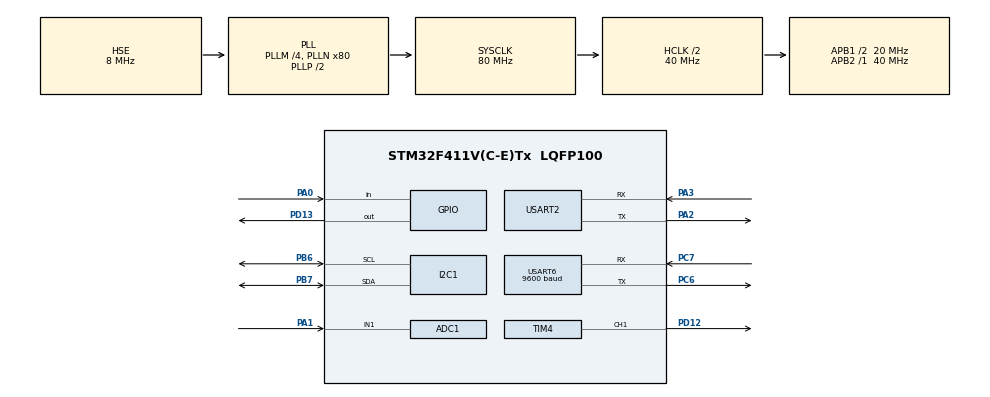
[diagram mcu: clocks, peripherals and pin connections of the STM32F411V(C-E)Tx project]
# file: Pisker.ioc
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ADC1.Channel-0\#ChannelRegularConversion=ADC_CHANNEL_1
ADC1.ClockPrescaler=ADC_CLOCK_SYNC_PCLK_DIV4
ADC1.ContinuousConvMode=ENABLE
ADC1.DMAContinuousRequests=ENABLE
ADC1.ExternalTrigConv=ADC_EXTERNALTRIGCONV_T3_TRGO
ADC1.NbrOfConversionFlag=1
ADC1.Rank-0\#ChannelRegularConversion=1
ADC1.SamplingTime-0\#ChannelRegularConversion=ADC_SAMPLETIME_3CYCLES
ADC1.master=1
Dma.ADC1.3.Direction=DMA_PERIPH_TO_MEMORY
Dma.ADC1.3.FIFOMode=DMA_FIFOMODE_DISABLE
Dma.ADC1.3.Instance=DMA2_Stream0
Dma.ADC1.3.MemDataAlignment=DMA_MDATAALIGN_HALFWORD
Dma.ADC1.3.MemInc=DMA_MINC_ENABLE
Dma.ADC1.3.Mode=DMA_CIRCULAR
Dma.ADC1.3.PeriphDataAlignment=DMA_PDATAALIGN_HALFWORD
Dma.ADC1.3.PeriphInc=DMA_PINC_DISABLE
Dma.ADC1.3.Priority=DMA_PRIORITY_LOW
Dma.Request0=TIM4_CH1
Dma.Request1=USART2_RX
Dma.Request2=USART6_RX
Dma.Request3=ADC1
Dma.TIM4_CH1.0.Direction=DMA_MEMORY_TO_PERIPH
Dma.TIM4_CH1.0.FIFOMode=DMA_FIFOMODE_DISABLE
Dma.TIM4_CH1.0.Instance=DMA1_Stream0
Dma.TIM4_CH1.0.MemDataAlignment=DMA_MDATAALIGN_HALFWORD
Dma.TIM4_CH1.0.MemInc=DMA_MINC_ENABLE
Dma.TIM4_CH1.0.Mode=DMA_NORMAL
Dma.TIM4_CH1.0.PeriphDataAlignment=DMA_PDATAALIGN_HALFWORD
Dma.TIM4_CH1.0.PeriphInc=DMA_PINC_DISABLE
Dma.TIM4_CH1.0.Priority=DMA_PRIORITY_LOW
Dma.USART2_RX.1.Direction=DMA_PERIPH_TO_MEMORY
Dma.USART2_RX.1.FIFOMode=DMA_FIFOMODE_DISABLE
Dma.USART2_RX.1.Instance=DMA1_Stream5
Dma.USART2_RX.1.MemDataAlignment=DMA_MDATAALIGN_BYTE
Dma.USART2_RX.1.MemInc=DMA_MINC_ENABLE
Dma.USART2_RX.1.Mode=DMA_CIRCULAR
Dma.USART2_RX.1.PeriphDataAlignment=DMA_PDATAALIGN_BYTE
Dma.USART2_RX.1.PeriphInc=DMA_PINC_DISABLE
Dma.USART2_RX.1.Priority=DMA_PRIORITY_LOW
Dma.USART6_RX.2.Direction=DMA_PERIPH_TO_MEMORY
Dma.USART6_RX.2.FIFOMode=DMA_FIFOMODE_DISABLE
Dma.USART6_RX.2.Instance=DMA2_Stream1
Dma.USART6_RX.2.MemDataAlignment=DMA_MDATAALIGN_BYTE
Dma.USART6_RX.2.MemInc=DMA_MINC_ENABLE
Dma.USART6_RX.2.Mode=DMA_CIRCULAR
Dma.USART6_RX.2.PeriphDataAlignment=DMA_PDATAALIGN_BYTE
Dma.USART6_RX.2.PeriphInc=DMA_PINC_DISABLE
Dma.USART6_RX.2.Priority=DMA_PRIORITY_LOW
Mcu.Family=STM32F4
Mcu.Name=STM32F411V(C-E)Tx
Mcu.Package=LQFP100
NVIC.DMA1_Stream0_IRQn=true\:0\:0\:false\:false\:true\:false\:true\:true
NVIC.DMA1_Stream5_IRQn=true\:0\:0\:false\:false\:true\:false\:true\:true
NVIC.DMA2_Stream0_IRQn=true\:0\:0\:false\:false\:true\:false\:true\:true
NVIC.DMA2_Stream1_IRQn=true\:0\:0\:false\:false\:true\:false\:true\:true
NVIC.I2C1_ER_IRQn=true\:0\:0\:false\:false\:true\:true\:true\:true
NVIC.I2C1_EV_IRQn=true\:0\:0\:false\:false\:true\:true\:true\:true
NVIC.PriorityGroup=NVIC_PRIORITYGROUP_4
NVIC.TIM3_IRQn=true\:0\:0\:false\:false\:true\:true\:true\:true
NVIC.TIM4_IRQn=true\:0\:0\:false\:false\:true\:true\:true\:true
NVIC.USART2_IRQn=true\:0\:0\:false\:false\:true\:true\:true\:true
NVIC.USART6_IRQn=true\:0\:0\:false\:false\:true\:true\:true\:true
PA0-WKUP.Signal=GPIO_Input
PA1.Signal=ADCx_IN1
PA13.Mode=Serial_Wire
PA13.Signal=SYS_JTMS-SWDIO
PA14.Mode=Serial_Wire
PA14.Signal=SYS_JTCK-SWCLK
PA2.Mode=Asynchronous
PA2.Signal=USART2_TX
PA3.Mode=Asynchronous
PA3.Signal=USART2_RX
PB6.Mode=I2C
PB6.Signal=I2C1_SCL
PB7.Mode=I2C
PB7.Signal=I2C1_SDA
PC6.Mode=Asynchronous
PC6.Signal=USART6_TX
PC7.Mode=Asynchronous
PC7.Signal=USART6_RX
PD12.Signal=S_TIM4_CH1
PD13.Signal=GPIO_Output
PH0\ -\ OSC_IN.Mode=HSE-External-Oscillator
PH0\ -\ OSC_IN.Signal=RCC_OSC_IN
PH1\ -\ OSC_OUT.Mode=HSE-External-Oscillator
PH1\ -\ OSC_OUT.Signal=RCC_OSC_OUT
ProjectManager.HeapSize=0x200
ProjectManager.StackSize=0x400
ProjectManager.TargetToolchain=STM32CubeIDE
RCC.48MHZClocksFreq_Value=40000000
RCC.AHBCLKDivider=RCC_SYSCLK_DIV2
RCC.AHBFreq_Value=40000000
RCC.APB1CLKDivider=RCC_HCLK_DIV2
RCC.APB1Freq_Value=20000000
RCC.APB1TimFreq_Value=40000000
RCC.APB2Freq_Value=40000000
RCC.APB2TimFreq_Value=40000000
RCC.CortexFreq_Value=40000000
RCC.HCLKFreq_Value=40000000
RCC.HSE_VALUE=8000000
RCC.HSI_VALUE=16000000
RCC.LSE_VALUE=32768
RCC.PLLI2SM=4
RCC.PLLI2SN=50
RCC.PLLM=4
RCC.PLLN=80
RCC.PLLSourceVirtual=RCC_PLLSOURCE_HSE
RCC.SYSCLKFreq_VALUE=80000000
RCC.SYSCLKSource=RCC_SYSCLKSOURCE_PLLCLK
RCC.VCOOutputFreq_Value=160000000
SH.ADCx_IN1.0=ADC1_IN1,IN1
SH.S_TIM4_CH1.0=TIM4_CH1,PWM Generation1 CH1
STMicroelectronics.X-CUBE-ALGOBUILD.1.4.0.LibraryCcDSPOoLibraryJjDSPOoLibrary=true
TIM3.Period=25-1
TIM3.Prescaler=100-1
TIM3.TIM_MasterOutputTrigger=TIM_TRGO_UPDATE
TIM4.Channel-PWM\ Generation1\ CH1=TIM_CHANNEL_1
TIM4.Period=50-1
USART2.VirtualMode=VM_ASYNC
USART6.BaudRate=9600
USART6.VirtualMode=VM_ASYNC
VP_STMicroelectronics.X-CUBE-ALGOBUILD_VS_DSPOoLibraryJjLibrary_1.4.0_1.4.0.Mode=DSPOoLibraryJjLibrary
VP_TIM3_VS_ClockSourceINT.Mode=Internal
board=custom

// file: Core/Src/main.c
/* USER CODE BEGIN Header */
/**
 ******************************************************************************
 * @file           : main.c
 * @brief          : Main program body
 ******************************************************************************
 * @attention
 *
 * Copyright (c) 2024 STMicroelectronics.
 * All rights reserved.
 *
 * This software is licensed under terms that can be found in the LICENSE file
 * in the root directory of this software component.
 * If no LICENSE file comes with this software, it is provided AS-IS.
 *
 ******************************************************************************
 */
/* USER CODE END Header */
#include "main.h"

ADC_HandleTypeDef hadc1;
DMA_HandleTypeDef hdma_adc1;

I2C_HandleTypeDef hi2c1;

TIM_HandleTypeDef htim3;
TIM_HandleTypeDef htim4;
DMA_HandleTypeDef hdma_tim4_ch1;

UART_HandleTypeDef huart2;
UART_HandleTypeDef huart6;
DMA_HandleTypeDef hdma_usart2_rx;
DMA_HandleTypeDef hdma_usart6_rx;

/* USER CODE BEGIN PV */
btn_info_t button_state;
uint8_t uart_tx_buffer[TX_BUFFER_SIZE];
uint8_t uart_rx_buffer[RX_BUFFER_SIZE];
uint8_t uart_main_buffer[MAIN_BUFFER_SIZE];
/* USER CODE END PV */

void SystemClock_Config(void);
static void MX_GPIO_Init(void);
static void MX_DMA_Init(void);
static void MX_I2C1_Init(void);
static void MX_TIM4_Init(void);
static void MX_USART2_UART_Init(void);
static void MX_ADC1_Init(void);
static void MX_USART6_UART_Init(void);
static void MX_TIM3_Init(void);

int main(void)
{

  /* MCU Configuration--------------------------------------------------------*/

  /* Reset of all peripherals, Initializes the Flash interface and the Systick. */
  HAL_Init();

  /* Configure the system clock */
  SystemClock_Config();

  /* Initialize all configured peripherals */
  MX_GPIO_Init();
  MX_DMA_Init();
  MX_I2C1_Init();
  MX_TIM4_Init();
  MX_USART2_UART_Init();
  MX_ADC1_Init();
  MX_USART6_UART_Init();
  MX_TIM3_Init();
  /* USER CODE BEGIN 2 */
  //Init bsp
  bsp_adc_init(&hadc1, &hdma_adc1);
  bsp_i2c_init(&hi2c1);
  bsp_tim_init(&htim4);
  bsp_uart_pc_control_init(&huart2, &hdma_usart2_rx);
  bsp_uart_pc_control_buffer_init(uart_tx_buffer, uart_rx_buffer, RX_BUFFER_SIZE);
  bsp_uart_start_pc_control_receive();
  bsp_uart_dfp_init(&huart6, &hdma_usart6_rx);
  //system init
  sys_manager_init();
  //start Timer
  HAL_TIM_Base_Start_IT(&htim3);
  /* USER CODE END 2 */

  /* Infinite loop */
  while (1)
  {

    /* USER CODE BEGIN 3 */
    sys_manager_run(&button_state);
  }
  /* USER CODE END 3 */
}

void SystemClock_Config(void)
{
  RCC_OscInitTypeDef RCC_OscInitStruct = {0};
  RCC_ClkInitTypeDef RCC_ClkInitStruct = {0};

  /** Configure the main internal regulator output voltage
   */
  __HAL_RCC_PWR_CLK_ENABLE();
  __HAL_PWR_VOLTAGESCALING_CONFIG(PWR_REGULATOR_VOLTAGE_SCALE1);

  /** Initializes the RCC Oscillators according to the specified parameters
   * in the RCC_OscInitTypeDef structure.
   */
  RCC_OscInitStruct.OscillatorType = RCC_OSCILLATORTYPE_HSE;
  RCC_OscInitStruct.HSEState = RCC_HSE_ON;
  RCC_OscInitStruct.PLL.PLLState = RCC_PLL_ON;
  RCC_OscInitStruct.PLL.PLLSource = RCC_PLLSOURCE_HSE;
  RCC_OscInitStruct.PLL.PLLM = 4;
  RCC_OscInitStruct.PLL.PLLN = 80;
  RCC_OscInitStruct.PLL.PLLP = RCC_PLLP_DIV2;
  RCC_OscInitStruct.PLL.PLLQ = 4;
  if (HAL_RCC_OscConfig(&RCC_OscInitStruct) != HAL_OK)
  {
    Error_Handler();
  }

  /** Initializes the CPU, AHB and APB buses clocks
   */
  RCC_ClkInitStruct.ClockType = RCC_CLOCKTYPE_HCLK | RCC_CLOCKTYPE_SYSCLK | RCC_CLOCKTYPE_PCLK1 | RCC_CLOCKTYPE_PCLK2;
  RCC_ClkInitStruct.SYSCLKSource = RCC_SYSCLKSOURCE_PLLCLK;
  RCC_ClkInitStruct.AHBCLKDivider = RCC_SYSCLK_DIV2;
  RCC_ClkInitStruct.APB1CLKDivider = RCC_HCLK_DIV2;
  RCC_ClkInitStruct.APB2CLKDivider = RCC_HCLK_DIV1;

  if (HAL_RCC_ClockConfig(&RCC_ClkInitStruct, FLASH_LATENCY_1) != HAL_OK)
  {
    Error_Handler();
  }
}

static void MX_ADC1_Init(void)
{

  ADC_ChannelConfTypeDef sConfig = {0};

  /** Configure the global features of the ADC (Clock, Resolution, Data Alignment and number of conversion)
   */
  hadc1.Instance = ADC1;
  hadc1.Init.ClockPrescaler = ADC_CLOCK_SYNC_PCLK_DIV4;
  hadc1.Init.Resolution = ADC_RESOLUTION_12B;
  hadc1.Init.ScanConvMode = DISABLE;
  hadc1.Init.ContinuousConvMode = ENABLE;
  hadc1.Init.DiscontinuousConvMode = DISABLE;
  hadc1.Init.ExternalTrigConvEdge = ADC_EXTERNALTRIGCONVEDGE_RISING;
  hadc1.Init.ExternalTrigConv = ADC_EXTERNALTRIGCONV_T3_TRGO;
  hadc1.Init.DataAlign = ADC_DATAALIGN_RIGHT;
  hadc1.Init.NbrOfConversion = 1;
  hadc1.Init.DMAContinuousRequests = ENABLE;
  hadc1.Init.EOCSelection = ADC_EOC_SINGLE_CONV;
  if (HAL_ADC_Init(&hadc1) != HAL_OK)
  {
    Error_Handler();
  }

  /** Configure for the selected ADC regular channel its corresponding rank in the sequencer and its sample time.
   */
  sConfig.Channel = ADC_CHANNEL_1;
  sConfig.Rank = 1;
  sConfig.SamplingTime = ADC_SAMPLETIME_3CYCLES;
  if (HAL_ADC_ConfigChannel(&hadc1, &sConfig) != HAL_OK)
  {
    Error_Handler();
  }
}

static void MX_I2C1_Init(void)
{

  hi2c1.Instance = I2C1;
  hi2c1.Init.ClockSpeed = 100000;
  hi2c1.Init.DutyCycle = I2C_DUTYCYCLE_2;
  hi2c1.Init.OwnAddress1 = 0;
  hi2c1.Init.AddressingMode = I2C_ADDRESSINGMODE_7BIT;
  hi2c1.Init.DualAddressMode = I2C_DUALADDRESS_DISABLE;
  hi2c1.Init.OwnAddress2 = 0;
  hi2c1.Init.GeneralCallMode = I2C_GENERALCALL_DISABLE;
  hi2c1.Init.NoStretchMode = I2C_NOSTRETCH_DISABLE;
  if (HAL_I2C_Init(&hi2c1) != HAL_OK)
  {
    Error_Handler();
  }
}

static void MX_TIM3_Init(void)
{

  TIM_ClockConfigTypeDef sClockSourceConfig = {0};
  TIM_MasterConfigTypeDef sMasterConfig = {0};

  htim3.Instance = TIM3;
  htim3.Init.Prescaler = 100 - 1;
  htim3.Init.CounterMode = TIM_COUNTERMODE_UP;
  htim3.Init.Period = 25 - 1;
  htim3.Init.ClockDivision = TIM_CLOCKDIVISION_DIV1;
  htim3.Init.AutoReloadPreload = TIM_AUTORELOAD_PRELOAD_DISABLE;
  if (HAL_TIM_Base_Init(&htim3) != HAL_OK)
  {
    Error_Handler();
  }
  sClockSourceConfig.ClockSource = TIM_CLOCKSOURCE_INTERNAL;
  if (HAL_TIM_ConfigClockSource(&htim3, &sClockSourceConfig) != HAL_OK)
  {
    Error_Handler();
  }
  sMasterConfig.MasterOutputTrigger = TIM_TRGO_UPDATE;
  sMasterConfig.MasterSlaveMode = TIM_MASTERSLAVEMODE_DISABLE;
  if (HAL_TIMEx_MasterConfigSynchronization(&htim3, &sMasterConfig) != HAL_OK)
  {
    Error_Handler();
  }
}

static void MX_TIM4_Init(void)
{

  TIM_MasterConfigTypeDef sMasterConfig = {0};
  TIM_OC_InitTypeDef sConfigOC = {0};

  htim4.Instance = TIM4;
  htim4.Init.Prescaler = 0;
  htim4.Init.CounterMode = TIM_COUNTERMODE_UP;
  htim4.Init.Period = 50 - 1;
  htim4.Init.ClockDivision = TIM_CLOCKDIVISION_DIV1;
  htim4.Init.AutoReloadPreload = TIM_AUTORELOAD_PRELOAD_DISABLE;
  if (HAL_TIM_PWM_Init(&htim4) != HAL_OK)
  {
    Error_Handler();
  }
  sMasterConfig.MasterOutputTrigger = TIM_TRGO_RESET;
  sMasterConfig.MasterSlaveMode = TIM_MASTERSLAVEMODE_DISABLE;
  if (HAL_TIMEx_MasterConfigSynchronization(&htim4, &sMasterConfig) != HAL_OK)
  {
    Error_Handler();
  }
  sConfigOC.OCMode = TIM_OCMODE_PWM1;
  sConfigOC.Pulse = 0;
  sConfigOC.OCPolarity = TIM_OCPOLARITY_HIGH;
  sConfigOC.OCFastMode = TIM_OCFAST_DISABLE;
  if (HAL_TIM_PWM_ConfigChannel(&htim4, &sConfigOC, TIM_CHANNEL_1) != HAL_OK)
  {
    Error_Handler();
  }
  HAL_TIM_MspPostInit(&htim4);
}

static void MX_USART2_UART_Init(void)
{

  huart2.Instance = USART2;
  huart2.Init.BaudRate = 115200;
  huart2.Init.WordLength = UART_WORDLENGTH_8B;
  huart2.Init.StopBits = UART_STOPBITS_1;
  huart2.Init.Parity = UART_PARITY_NONE;
  huart2.Init.Mode = UART_MODE_TX_RX;
  huart2.Init.HwFlowCtl = UART_HWCONTROL_NONE;
  huart2.Init.OverSampling = UART_OVERSAMPLING_16;
  if (HAL_UART_Init(&huart2) != HAL_OK)
  {
    Error_Handler();
  }
}

static void MX_USART6_UART_Init(void)
{

  huart6.Instance = USART6;
  huart6.Init.BaudRate = 9600;
  huart6.Init.WordLength = UART_WORDLENGTH_8B;
  huart6.Init.StopBits = UART_STOPBITS_1;
  huart6.Init.Parity = UART_PARITY_NONE;
  huart6.Init.Mode = UART_MODE_TX_RX;
  huart6.Init.HwFlowCtl = UART_HWCONTROL_NONE;
  huart6.Init.OverSampling = UART_OVERSAMPLING_16;
  if (HAL_UART_Init(&huart6) != HAL_OK)
  {
    Error_Handler();
  }
}

static void MX_DMA_Init(void)
{

  /* DMA controller clock enable */
  __HAL_RCC_DMA1_CLK_ENABLE();
  __HAL_RCC_DMA2_CLK_ENABLE();

  /* DMA interrupt init */
  /* DMA1_Stream0_IRQn interrupt configuration */
  HAL_NVIC_SetPriority(DMA1_Stream0_IRQn, 0, 0);
  HAL_NVIC_EnableIRQ(DMA1_Stream0_IRQn);
  /* DMA1_Stream5_IRQn interrupt configuration */
  HAL_NVIC_SetPriority(DMA1_Stream5_IRQn, 0, 0);
  HAL_NVIC_EnableIRQ(DMA1_Stream5_IRQn);
  /* DMA2_Stream0_IRQn interrupt configuration */
  HAL_NVIC_SetPriority(DMA2_Stream0_IRQn, 0, 0);
  HAL_NVIC_EnableIRQ(DMA2_Stream0_IRQn);
  /* DMA2_Stream1_IRQn interrupt configuration */
  HAL_NVIC_SetPriority(DMA2_Stream1_IRQn, 0, 0);
  HAL_NVIC_EnableIRQ(DMA2_Stream1_IRQn);
}

static void MX_GPIO_Init(void)
{
  GPIO_InitTypeDef GPIO_InitStruct = {0};

  /* GPIO Ports Clock Enable */
  __HAL_RCC_GPIOH_CLK_ENABLE();
  __HAL_RCC_GPIOA_CLK_ENABLE();
  __HAL_RCC_GPIOD_CLK_ENABLE();
  __HAL_RCC_GPIOC_CLK_ENABLE();
  __HAL_RCC_GPIOB_CLK_ENABLE();

  /*Configure GPIO pin Output Level */
  HAL_GPIO_WritePin(GPIOD, GPIO_PIN_13, GPIO_PIN_RESET);

  /*Configure GPIO pin : PA0 */
  GPIO_InitStruct.Pin = GPIO_PIN_0;
  GPIO_InitStruct.Mode = GPIO_MODE_INPUT;
  GPIO_InitStruct.Pull = GPIO_NOPULL;
  HAL_GPIO_Init(GPIOA, &GPIO_InitStruct);

  /*Configure GPIO pin : PD13 */
  GPIO_InitStruct.Pin = GPIO_PIN_13;
  GPIO_InitStruct.Mode = GPIO_MODE_OUTPUT_PP;
  GPIO_InitStruct.Pull = GPIO_NOPULL;
  GPIO_InitStruct.Speed = GPIO_SPEED_FREQ_LOW;
  HAL_GPIO_Init(GPIOD, &GPIO_InitStruct);

}

void Error_Handler(void)
{
  __disable_irq();
  while (1)
  {
  }
}
